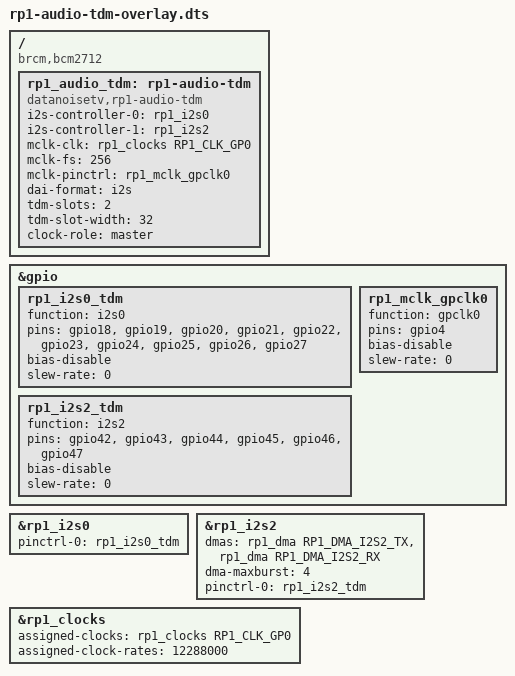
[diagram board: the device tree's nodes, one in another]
/*
 * Device tree overlay for RP1 multi-peripheral I2S/TDM audio
 *
 * Enables i2s0 (GPIO18-27, up to 8ch) and optionally i2s2 (GPIO42-47,
 * up to 4ch full-duplex) with configurable TDM or standard I2S mode.
 *
 * MCLK output can optionally be provided via GPCLK0 on GPIO4, derived
 * from pll_audio through clk_i2s for sample-synchronous operation.
 *
 * Copyright (c) 2026 DatanoiseTV
 * SPDX-License-Identifier: GPL-2.0
 */

/dts-v1/;
/plugin/;

#include <dt-bindings/gpio/gpio.h>
#include <dt-bindings/clock/rp1.h>
#include <dt-bindings/mfd/rp1.h>

/ {
	compatible = "brcm,bcm2712";

	/* ----------------------------------------------------------
	 * Fragment 0: GPIO pinctrl for i2s0 on GPIO18-27 (10 pins)
	 *   GPIO18 = BCLK, GPIO19 = LRCLK
	 *   GPIO20-27 = SD0-SD7 (up to 4 TX + 4 RX data lines)
	 * ---------------------------------------------------------- */
	fragment@0 {
		target = <&gpio>;
		__overlay__ {
			rp1_i2s0_tdm: rp1_i2s0_tdm {
				function = "i2s0";
				pins = "gpio18", "gpio19", "gpio20",
				       "gpio21", "gpio22", "gpio23",
				       "gpio24", "gpio25", "gpio26",
				       "gpio27";
				bias-disable;
				slew-rate = <0>;
			};
		};
	};

	/* ----------------------------------------------------------
	 * Fragment 1: GPIO pinctrl for i2s2 on GPIO42-47 (6 pins)
	 *   GPIO42 = BCLK, GPIO43 = LRCLK
	 *   GPIO44-47 = SD0-SD3 (up to 2 TX + 2 RX data lines)
	 * ---------------------------------------------------------- */
	fragment@1 {
		target = <&gpio>;
		__overlay__ {
			rp1_i2s2_tdm: rp1_i2s2_tdm {
				function = "i2s2";
				pins = "gpio42", "gpio43", "gpio44",
				       "gpio45", "gpio46", "gpio47";
				bias-disable;
				slew-rate = <0>;
			};
		};
	};

	/* ----------------------------------------------------------
	 * Fragment 2: GPIO pinctrl for MCLK output on GPIO4 (gpclk0)
	 * ---------------------------------------------------------- */
	fragment@2 {
		target = <&gpio>;
		__overlay__ {
			rp1_mclk_gpclk0: rp1_mclk_gpclk0 {
				function = "gpclk0";
				pins = "gpio4";
				bias-disable;
				slew-rate = <0>;
			};
		};
	};

	/* ----------------------------------------------------------
	 * Fragment 3: Enable i2s0 with full pinctrl and DMA
	 * ---------------------------------------------------------- */
	fragment@3 {
		target = <&rp1_i2s0>;
		__overlay__ {
			pinctrl-names = "default";
			pinctrl-0 = <&rp1_i2s0_tdm>;
			#sound-dai-cells = <0>;
			status = "okay";
		};
	};

	/* ----------------------------------------------------------
	 * Fragment 4: Enable i2s2 with DMA (missing in base DT)
	 * ---------------------------------------------------------- */
	fragment@4 {
		target = <&rp1_i2s2>;
		__overlay__ {
			clock-names = "i2sclk";
			#sound-dai-cells = <0>;
			dmas = <&rp1_dma RP1_DMA_I2S2_TX>,
			       <&rp1_dma RP1_DMA_I2S2_RX>;
			dma-names = "tx", "rx";
			dma-maxburst = <4>;
			pinctrl-names = "default";
			pinctrl-0 = <&rp1_i2s2_tdm>;
			status = "okay";
		};
	};

	/* ----------------------------------------------------------
	 * Fragment 5: GPCLK0 configuration for MCLK output
	 * Parented to pll_audio via clk_i2s for synchronous clocking.
	 * Default: 12.288 MHz (256 * 48kHz)
	 * ---------------------------------------------------------- */
	fragment@5 {
		target = <&rp1_clocks>;
		__overlay__ {
			assigned-clocks = <&rp1_clocks RP1_CLK_GP0>;
			assigned-clock-rates = <12288000>;
		};
	};

	/* ----------------------------------------------------------
	 * Fragment 6: Sound card node for the machine driver
	 * ---------------------------------------------------------- */
	fragment@6 {
		target-path = "/";
		__overlay__ {
			rp1_audio_tdm: rp1-audio-tdm {
				compatible = "datanoisetv,rp1-audio-tdm";
				status = "okay";

				/* Primary I2S controller (8ch capable) */
				i2s-controller-0 = <&rp1_i2s0>;

				/* Secondary I2S controller (4ch full-duplex) */
				i2s-controller-1 = <&rp1_i2s2>;

				/*
				 * MCLK output via GPCLK0 on GPIO4.
				 * Set mclk-fs to the desired MCLK/fs ratio.
				 * Common values: 256 (12.288 MHz @ 48k),
				 *                384 (18.432 MHz @ 48k),
				 *                512 (24.576 MHz @ 48k)
				 * Set to 0 or omit to disable MCLK output.
				 */
				mclk-clk = <&rp1_clocks RP1_CLK_GP0>;
				mclk-fs = <256>;
				mclk-pinctrl = <&rp1_mclk_gpclk0>;

				/*
				 * TDM / I2S configuration defaults.
				 * These can be overridden via the __overrides__
				 * section below from config.txt.
				 *
				 * dai-format: "i2s", "dsp-a", "dsp-b",
				 *             "left-j", "right-j"
				 * tdm-slots:  2 = standard I2S, 4/8/16 = TDM
				 * tdm-slot-width: always 32 for DWC I2S
				 */
				dai-format = "i2s";
				tdm-slots = <2>;
				tdm-slot-width = <32>;

				/*
				 * Clock role: "master" or "slave"
				 * Master: RPi generates BCLK + LRCLK
				 * Slave: external codec generates BCLK + LRCLK
				 *
				 * TDM with >2 slots in master mode requires
				 * the kernel patch from patches/ directory.
				 */
				clock-role = "master";
			};
		};
	};

	/* ----------------------------------------------------------
	 * Runtime parameters configurable from /boot/config.txt:
	 *   dtoverlay=rp1-audio-tdm,tdm_slots=8,dai_fmt=dsp-a
	 * ---------------------------------------------------------- */
	__overrides__ {
		dai_fmt =       <&rp1_audio_tdm>, "dai-format";
		tdm_slots =     <&rp1_audio_tdm>, "tdm-slots:0";
		tdm_slot_width = <&rp1_audio_tdm>, "tdm-slot-width:0";
		clock_role =    <&rp1_audio_tdm>, "clock-role";
		mclk_fs =       <&rp1_audio_tdm>, "mclk-fs:0";
		enable_i2s2 =   <&rp1_i2s2>, "status",
				<&rp1_audio_tdm>, "i2s-controller-1?";
		enable_mclk =   <&rp1_audio_tdm>, "mclk-clk?",
				<&rp1_audio_tdm>, "mclk-pinctrl?";
	};
};
